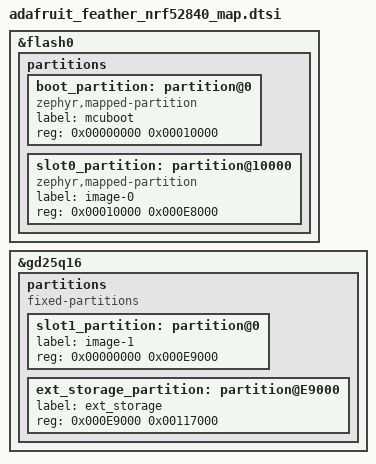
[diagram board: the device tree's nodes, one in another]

/* Expand internal MCUboot and Slot0 partitions */
&flash0 {
    partitions {
        ranges;
        #address-cells = <1>;
        #size-cells = <1>;

		/* Delete the default board partitions that start at 0xc000 and 0x82000 */
        /delete-node/ partition@c000;
        /delete-node/ partition@82000;

        /* 1. MCUboot partition increased to 64KB (0x10000) */
        boot_partition: partition@0 {
            compatible = "zephyr,mapped-partition";
            label = "mcuboot";
            reg = <0x00000000 0x00010000>;
        };

        /* 2. Slot 0 starts at 0x10000 and uses remaining internal flash */
        slot0_partition: partition@10000 {
            compatible = "zephyr,mapped-partition";
            label = "image-0";
            reg = <0x00010000 0x000E8000>;
        };

        /* 3. Storage partition from 0xF8000 -> 0xFFFFF */
    };
};

&gd25q16 {
    status = "okay";
    partitions {
        compatible = "fixed-partitions";
        #address-cells = <1>;
        #size-cells = <1>;

        /* MCUboot secondary slot - One page larger than slot0 (swap page) */
        slot1_partition: partition@0 {
            label = "image-1";
            reg = <0x00000000 0x000E9000>;
        };

        /* Rest of the 16Mbit (2MB) Flash */
        ext_storage_partition: partition@E9000 {
            label = "ext_storage";
            reg = <0x000E9000 0x00117000>;
        };
    };
};

